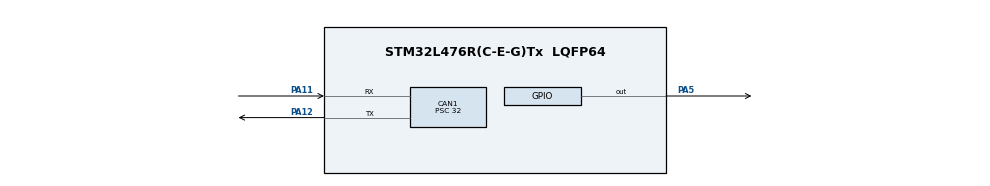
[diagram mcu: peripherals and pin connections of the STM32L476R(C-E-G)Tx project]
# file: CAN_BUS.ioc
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CAN1.BS1=CAN_BS1_3TQ
CAN1.CalculateBaudRate=500000
CAN1.CalculateTimeBit=2000
CAN1.CalculateTimeQuantum=400.0
CAN1.Prescaler=32
Mcu.Family=STM32L4
Mcu.Name=STM32L476R(C-E-G)Tx
Mcu.Package=LQFP64
NVIC.CAN1_RX0_IRQn=true\:0\:0\:false\:false\:true\:true\:true\:true
NVIC.PriorityGroup=NVIC_PRIORITYGROUP_4
PA11.GPIO_PuPd=GPIO_PULLUP
PA11.Mode=CAN_Activate
PA11.Signal=CAN1_RX
PA12.Mode=CAN_Activate
PA12.Signal=CAN1_TX
PA5.Signal=GPIO_Output
PH0-OSC_IN\ (PH0).Mode=HSE-External-Oscillator
PH0-OSC_IN\ (PH0).Signal=RCC_OSC_IN
PH1-OSC_OUT\ (PH1).Mode=HSE-External-Oscillator
PH1-OSC_OUT\ (PH1).Signal=RCC_OSC_OUT
ProjectManager.HeapSize=0x200
ProjectManager.StackSize=0x400
ProjectManager.TargetToolchain=STM32CubeIDE
RCC.ADCFreq_Value=16000000
RCC.AHBFreq_Value=80000000
RCC.APB1Freq_Value=80000000
RCC.APB1TimFreq_Value=80000000
RCC.APB2Freq_Value=80000000
RCC.APB2TimFreq_Value=80000000
RCC.CortexFreq_Value=80000000
RCC.HCLKFreq_Value=80000000
RCC.HSE_VALUE=8000000
RCC.HSI_VALUE=16000000
RCC.LSE_VALUE=32768
RCC.MSI_VALUE=4000000
RCC.PLLN=40
RCC.SYSCLKFreq_VALUE=80000000
RCC.SYSCLKSource=RCC_SYSCLKSOURCE_PLLCLK
RCC.USBFreq_Value=16000000
RCC.VCOOutputFreq_Value=160000000
board=custom

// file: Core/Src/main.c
/* USER CODE BEGIN Header */
/**
  ******************************************************************************
  * @file           : main.c
  * @brief          : Main program body
  ******************************************************************************
  * @attention
  *
  * Copyright (c) 2024 STMicroelectronics.
  * All rights reserved.
  *
  * This software is licensed under terms that can be found in the LICENSE file
  * in the root directory of this software component.
  * If no LICENSE file comes with this software, it is provided AS-IS.
  *
  ******************************************************************************
  */
/* USER CODE END Header */
#include "main.h"

/* USER CODE BEGIN Includes */
#include "communication.h"
#include "stdio.h"
/* USER CODE END Includes */

CAN_HandleTypeDef hcan1;

void SystemClock_Config(void);
static void MX_GPIO_Init(void);
static void MX_CAN1_Init(void);

/* USER CODE BEGIN 0 */
uint8_t uart_command[LINE_MAX_LENGTH] = {0};

CAN_TxHeaderTypeDef TxHeader;
CAN_RxHeaderTypeDef RxHeader;

uint8_t TxData[8] = {0};
uint8_t RxData[8] = {0};

uint32_t TxMailbox;

void usart_append(uint8_t value){
	static char line_buffer_usart[LINE_MAX_LENGTH + 1];
	static uint8_t line_length_usart = 0;

	if(value == '\r'){
		line_buffer_usart[line_length_usart] = '\0';
		printf("Received: %s\r\n", line_buffer_usart);
		strcpy((char *)uart_command, line_buffer_usart);
		memset(line_buffer_usart, '\0', LINE_MAX_LENGTH);
		line_length_usart = 0;
	}
	else
	{
		if (line_length_usart >= LINE_MAX_LENGTH) {
			line_length_usart = 0;
		}
		line_buffer_usart[line_length_usart++] = value;
	}
}

void HAL_CAN_RxFifo0MsgPendingCallback(CAN_HandleTypeDef *hcan){
	HAL_CAN_GetRxMessage(&hcan1, CAN_RX_FIFO0, &RxHeader, RxData);
}

/* USER CODE END 0 */

int main(void)
{

  /* MCU Configuration--------------------------------------------------------*/

  /* Reset of all peripherals, Initializes the Flash interface and the Systick. */
  HAL_Init();

  /* Configure the system clock */
  SystemClock_Config();

  /* Initialize all configured peripherals */
  MX_GPIO_Init();
  MX_CAN1_Init();
  /* USER CODE BEGIN 2 */
  HAL_CAN_Start(&hcan1);
  usart2_init();

  TxHeader.IDE = CAN_ID_STD;
  TxHeader.RTR = CAN_RTR_DATA;

  HAL_CAN_ActivateNotification(&hcan1, CAN_IT_RX_FIFO0_MSG_PENDING);
  /* USER CODE END 2 */

  /* Infinite loop */
  /* USER CODE BEGIN WHILE */
  printf("Siemanderko\r\n");
  TxHeader.StdId = 0x101;
	TxHeader.DLC = 1;
	TxData[0] = 11;
//	HAL_CAN_AddTxMessage(&hcan1, &TxHeader, TxData, &TxMailbox);
  while (1){
  	if(!strncmp((const char*)uart_command, "cm1", 3)){ //comand that awaits for answer
  		TxHeader.StdId = 0x101;
			TxHeader.DLC = 1;
			TxData[0] = 11;
  		HAL_CAN_AddTxMessage(&hcan1, &TxHeader, TxData, &TxMailbox);
  		HAL_Delay(10);
  		printf("Got an answer: %d \r\n", RxData[0]);
  		memset(uart_command, '\0', LINE_MAX_LENGTH);
  	}
  	else if(!strncmp((const char*)uart_command, "cm2", 3)){ //command that tells how many times it needs to blink
  		uint8_t s_delay = uart_command[4];
  		uint8_t blink_amount = uart_command[6];
  		if(s_delay && blink_amount){
  			TxHeader.StdId = 0x102;
				TxHeader.DLC = 2;
				TxData[0] = s_delay - 48;
				TxData[1] = blink_amount - 48;
				HAL_CAN_AddTxMessage(&hcan1, &TxHeader, TxData, &TxMailbox);
  		}
  		else
  			printf("An error in the command\r\n");
  		memset(uart_command, '\0', LINE_MAX_LENGTH);
  	}
  	else if(!strncmp((const char*)uart_command, "cm3", 3)){ //command that gets ignored, cause of bad id
  		uint8_t s_delay = uart_command[4];
			uint8_t blink_amount = uart_command[6];
			if(s_delay && blink_amount){
				TxHeader.StdId = 0x003;
				TxHeader.DLC = 2;
				TxData[0] = s_delay;
				TxData[1] = blink_amount;
				HAL_CAN_AddTxMessage(&hcan1, &TxHeader, TxData, &TxMailbox);
			}
			else
				printf("An error in the command\r\n");
			memset(uart_command, '\0', LINE_MAX_LENGTH);
  	}

    /* USER CODE END WHILE */

  }
}

void SystemClock_Config(void)
{
  LL_FLASH_SetLatency(LL_FLASH_LATENCY_4);
  while(LL_FLASH_GetLatency()!= LL_FLASH_LATENCY_4)
  {
  }
  LL_PWR_SetRegulVoltageScaling(LL_PWR_REGU_VOLTAGE_SCALE1);
  while (LL_PWR_IsActiveFlag_VOS() != 0)
  {
  }
  LL_RCC_MSI_Enable();

   /* Wait till MSI is ready */
  while(LL_RCC_MSI_IsReady() != 1)
  {

  }
  LL_RCC_MSI_EnableRangeSelection();
  LL_RCC_MSI_SetRange(LL_RCC_MSIRANGE_6);
  LL_RCC_MSI_SetCalibTrimming(0);
  LL_RCC_PLL_ConfigDomain_SYS(LL_RCC_PLLSOURCE_MSI, LL_RCC_PLLM_DIV_1, 40, LL_RCC_PLLR_DIV_2);
  LL_RCC_PLL_EnableDomain_SYS();
  LL_RCC_PLL_Enable();

   /* Wait till PLL is ready */
  while(LL_RCC_PLL_IsReady() != 1)
  {

  }
  LL_RCC_SetSysClkSource(LL_RCC_SYS_CLKSOURCE_PLL);

   /* Wait till System clock is ready */
  while(LL_RCC_GetSysClkSource() != LL_RCC_SYS_CLKSOURCE_STATUS_PLL)
  {

  }
  LL_RCC_SetAHBPrescaler(LL_RCC_SYSCLK_DIV_1);
  LL_RCC_SetAPB1Prescaler(LL_RCC_APB1_DIV_1);
  LL_RCC_SetAPB2Prescaler(LL_RCC_APB2_DIV_1);
  LL_SetSystemCoreClock(80000000);

   /* Update the time base */
  if (HAL_InitTick (TICK_INT_PRIORITY) != HAL_OK)
  {
    Error_Handler();
  }
}

static void MX_CAN1_Init(void)
{

  hcan1.Instance = CAN1;
  hcan1.Init.Prescaler = 32;
  hcan1.Init.Mode = CAN_MODE_NORMAL;
  hcan1.Init.SyncJumpWidth = CAN_SJW_1TQ;
  hcan1.Init.TimeSeg1 = CAN_BS1_3TQ;
  hcan1.Init.TimeSeg2 = CAN_BS2_1TQ;
  hcan1.Init.TimeTriggeredMode = DISABLE;
  hcan1.Init.AutoBusOff = DISABLE;
  hcan1.Init.AutoWakeUp = DISABLE;
  hcan1.Init.AutoRetransmission = DISABLE;
  hcan1.Init.ReceiveFifoLocked = DISABLE;
  hcan1.Init.TransmitFifoPriority = DISABLE;
  if (HAL_CAN_Init(&hcan1) != HAL_OK)
  {
    Error_Handler();
  }
  /* USER CODE BEGIN CAN1_Init 2 */
  CAN_FilterTypeDef canfilterconfig;

	canfilterconfig.FilterActivation = CAN_FILTER_ENABLE;
	canfilterconfig.FilterBank = 10;  // anything between 0 to SlaveStartFilterBank
	canfilterconfig.FilterFIFOAssignment = CAN_RX_FIFO0;
	canfilterconfig.FilterIdHigh = 0x000;
	canfilterconfig.FilterIdLow = 0x0000;
	canfilterconfig.FilterMaskIdHigh = 0x000;
	canfilterconfig.FilterMaskIdLow = 0x0000;
	canfilterconfig.FilterMode = CAN_FILTERMODE_IDMASK;
	canfilterconfig.FilterScale = CAN_FILTERSCALE_32BIT;
	canfilterconfig.SlaveStartFilterBank = 13;  // 13 to 27 are assigned to slave CAN (CAN 2) OR 0 to 12 are assgned to CAN1

	HAL_CAN_ConfigFilter(&hcan1, &canfilterconfig);
  /* USER CODE END CAN1_Init 2 */

}

static void MX_GPIO_Init(void)
{
  LL_GPIO_InitTypeDef GPIO_InitStruct = {0};

  /* GPIO Ports Clock Enable */
  LL_AHB2_GRP1_EnableClock(LL_AHB2_GRP1_PERIPH_GPIOH);
  LL_AHB2_GRP1_EnableClock(LL_AHB2_GRP1_PERIPH_GPIOA);

  /**/
  LL_GPIO_ResetOutputPin(GPIOA, LL_GPIO_PIN_5);

  /**/
  GPIO_InitStruct.Pin = LL_GPIO_PIN_5;
  GPIO_InitStruct.Mode = LL_GPIO_MODE_OUTPUT;
  GPIO_InitStruct.Speed = LL_GPIO_SPEED_FREQ_LOW;
  GPIO_InitStruct.OutputType = LL_GPIO_OUTPUT_PUSHPULL;
  GPIO_InitStruct.Pull = LL_GPIO_PULL_NO;
  LL_GPIO_Init(GPIOA, &GPIO_InitStruct);

}

void Error_Handler(void)
{
  __disable_irq();
  while (1)
  {
  }
}
